AUTOSAR XML (schema 00044)
package /VehicleProject
  system System
    system mapping System_MPPNG
      data-mappings:
        data-element=VehSpd.VehSpd, system-signal=VehSpd
        data-element=Hr.Hr, system-signal=Hr
        data-element=Mth.Mth, system-signal=Mth
        data-element=ComfEna.ComfEna, system-signal=ComfEna
        data-element=VehState.VehState, system-signal=VehState
        data-element=Yr.Yr, system-signal=Yr
        data-element=CGW_03_CRC.CGW_03_CRC, system-signal=CGW_03_CRC
        data-element=WLCChrgFctEnaReq.WLCChrgFctEnaReq, system-signal=WLCChrgFctEnaReq
        data-element=Day.Day, system-signal=Day
        data-element=CGW_03_MsgCntr.CGW_03_MsgCntr, system-signal=CGW_03_MsgCntr
        system-signal=VehSpd
        data-element=Sec.Sec, system-signal=Sec
        data-element=VehOdometer.VehOdometer, system-signal=VehOdometer
        data-element=Min.Min, system-signal=Min
        data-element=VehState_ASIL.VehState_ASIL, system-signal=VehState_ASIL
        data-element=ComfEna_ASIL.ComfEna_ASIL, system-signal=ComfEna_ASIL
        data-element=ImobEnaReq.ImobEnaReq, system-signal=ImobEnaReq
        data-element=CGW_WLC_MsgCntr.CGW_WLC_MsgCntr, system-signal=CGW_WLC_MsgCntr
        data-element=CGW_WLC_CRC.CGW_WLC_CRC, system-signal=CGW_WLC_CRC
        data-element=WLC_02_CRC, system-signal=WLC_02_CRC
        data-element=WLCImobSts.WLCImobSts, system-signal=WLCImobSts
        data-element=UsrData0_WLC.UsrData0_WLC, system-signal=UsrData0_WLC
        data-element=WLC_01_MsgCntr.WLC_01_MsgCntr, system-signal=WLC_01_MsgCntr
        data-element=WLCChrgSts.WLCChrgSts, system-signal=WLCChrgSts
        data-element=WLCCtrlSts.WLCCtrlSts, system-signal=WLCCtrlSts
        data-element=WLC_02_MsgCntr.WLC_02_MsgCntr, system-signal=WLC_02_MsgCntr
        data-element=UsrData4_WLC.UsrData4_WLC, system-signal=UsrData4_WLC
        data-element=UsrData3_WLC.UsrData3_WLC, system-signal=UsrData3_WLC
        data-element=UsrData1_WLC.UsrData1_WLC, system-signal=UsrData1_WLC
        data-element=WLCFailSts.WLCFailSts, system-signal=WLCFailSts
        data-element=WLC_01_CRC.WLC_01_CRC, system-signal=WLC_01_CRC
        data-element=WLCMuteViaHW.WLCMuteViaHW, system-signal=WLCMuteViaHW
        data-element=UsrData2_WLC.UsrData2_WLC, system-signal=UsrData2_WLC
        data-element=UsrData5_WLC.UsrData5_WLC, system-signal=UsrData5_WLC
        data-element=WLCChrgRate.WLCChrgRate, system-signal=WLCChrgRate
    root-software-compositions:
      root sw composition prototype EcuSwComposition: software-composition=ECU_Composition
package /ECUCompositionTypes
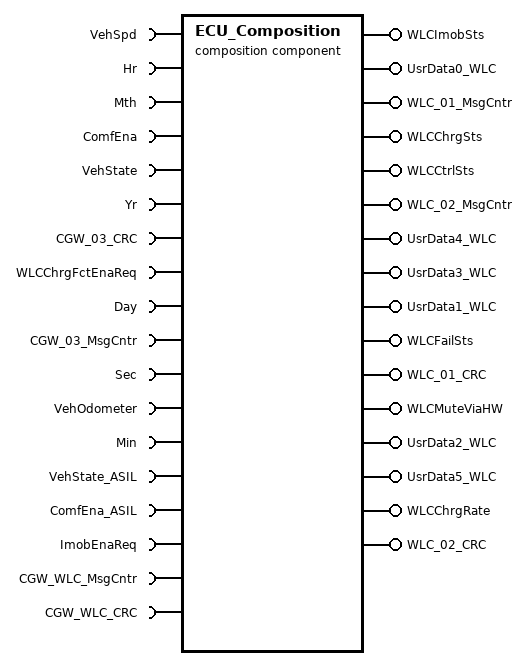
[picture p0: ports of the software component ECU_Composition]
  composition sw component type ECU_Composition
    18 x require port:
      VehSpd: nonqueued-receiver-com-spec{data-element=VehSpd, init-value=0}, required-interface=VehSpd
      Hr: nonqueued-receiver-com-spec{data-element=Hr, init-value=0}, required-interface=Hr
      Mth: nonqueued-receiver-com-spec{data-element=Mth, init-value=0}, required-interface=Mth
      ComfEna: nonqueued-receiver-com-spec{data-element=ComfEna, init-value=0}, required-interface=ComfEna
      VehState: nonqueued-receiver-com-spec{data-element=VehState, init-value=0}, required-interface=VehState
      Yr: nonqueued-receiver-com-spec{data-element=Yr, init-value=0}, required-interface=Yr
      CGW_03_CRC: nonqueued-receiver-com-spec{data-element=CGW_03_CRC, init-value=0}, required-interface=CGW_03_CRC
      WLCChrgFctEnaReq: nonqueued-receiver-com-spec{data-element=WLCChrgFctEnaReq, init-value=0}, required-interface=WLCChrgFctEnaReq
      Day: nonqueued-receiver-com-spec{data-element=Day, init-value=0}, required-interface=Day
      CGW_03_MsgCntr: nonqueued-receiver-com-spec{data-element=CGW_03_MsgCntr, init-value=0}, required-interface=CGW_03_MsgCntr
      Sec: nonqueued-receiver-com-spec{data-element=Sec, init-value=0}, required-interface=Sec
      VehOdometer: nonqueued-receiver-com-spec{data-element=VehOdometer, init-value=0}, required-interface=VehOdometer
      Min: nonqueued-receiver-com-spec{data-element=Min, init-value=0}, required-interface=Min
      VehState_ASIL: nonqueued-receiver-com-spec{data-element=VehState_ASIL, init-value=0}, required-interface=VehState_ASIL
      ComfEna_ASIL: nonqueued-receiver-com-spec{data-element=ComfEna_ASIL, init-value=0}, required-interface=ComfEna_ASIL
      ImobEnaReq: nonqueued-receiver-com-spec{data-element=ImobEnaReq, init-value=0}, required-interface=ImobEnaReq
      CGW_WLC_MsgCntr: nonqueued-receiver-com-spec{data-element=CGW_WLC_MsgCntr, init-value=0}, required-interface=CGW_WLC_MsgCntr
      CGW_WLC_CRC: nonqueued-receiver-com-spec{data-element=CGW_WLC_CRC, init-value=0}, required-interface=CGW_WLC_CRC
    16 x provide port:
      WLCImobSts: nonqueued-sender-com-spec{data-element=WLCImobSts, init-value=0}, provided-interface=WLCImobSts
      UsrData0_WLC: nonqueued-sender-com-spec{data-element=UsrData0_WLC, init-value=0}, provided-interface=UsrData0_WLC
      WLC_01_MsgCntr: nonqueued-sender-com-spec{data-element=WLC_01_MsgCntr, init-value=0}, provided-interface=WLC_01_MsgCntr
      WLCChrgSts: nonqueued-sender-com-spec{data-element=WLCChrgSts, init-value=0}, provided-interface=WLCChrgSts
      WLCCtrlSts: nonqueued-sender-com-spec{data-element=WLCCtrlSts, init-value=0}, provided-interface=WLCCtrlSts
      WLC_02_MsgCntr: nonqueued-sender-com-spec{data-element=WLC_02_MsgCntr, init-value=0}, provided-interface=WLC_02_MsgCntr
      UsrData4_WLC: nonqueued-sender-com-spec{data-element=UsrData4_WLC, init-value=0}, provided-interface=UsrData4_WLC
      UsrData3_WLC: nonqueued-sender-com-spec{data-element=UsrData3_WLC, init-value=0}, provided-interface=UsrData3_WLC
      UsrData1_WLC: nonqueued-sender-com-spec{data-element=UsrData1_WLC, init-value=0}, provided-interface=UsrData1_WLC
      WLCFailSts: nonqueued-sender-com-spec{data-element=WLCFailSts, init-value=0}, provided-interface=WLCFailSts
      WLC_01_CRC: nonqueued-sender-com-spec{data-element=WLC_01_CRC, init-value=0}, provided-interface=WLC_01_CRC
      WLCMuteViaHW: nonqueued-sender-com-spec{data-element=WLCMuteViaHW, init-value=0}, provided-interface=WLCMuteViaHW
      UsrData2_WLC: nonqueued-sender-com-spec{data-element=UsrData2_WLC, init-value=0}, provided-interface=UsrData2_WLC
      UsrData5_WLC: nonqueued-sender-com-spec{data-element=UsrData5_WLC, init-value=0}, provided-interface=UsrData5_WLC
      WLCChrgRate: nonqueued-sender-com-spec{data-element=WLCChrgRate, init-value=0}, provided-interface=WLCChrgRate
      WLC_02_CRC: nonqueued-sender-com-spec=WLC_02_CRC, provided-interface=WLC_02_CRC
    component SWC_WLCAPP: type=SWC_WLCAPP
    component Communication_Read_APP: type=Communication_Read_APP
    delegate Communication_Read_APP.Yr <-> outer port Yr
    delegate Communication_Read_APP.Hr <-> outer port Hr
    delegate Communication_Read_APP.Min <-> outer port Min
    delegate Communication_Read_APP.WLCChrgFctEnaReq <-> outer port WLCChrgFctEnaReq
    delegate Communication_Read_APP.ImobEnaReq <-> outer port ImobEnaReq
    delegate Communication_Read_APP.CGW_WLC_MsgCntr <-> outer port CGW_WLC_MsgCntr
    delegate Communication_Read_APP.VehOdometer <-> outer port VehOdometer
    delegate Communication_Read_APP.CGW_WLC_CRC <-> outer port CGW_WLC_CRC
    delegate Communication_Read_APP.CGW_03_MsgCntr <-> outer port CGW_03_MsgCntr
    delegate Communication_Read_APP.ComfEna_ASIL <-> outer port ComfEna_ASIL
    delegate Communication_Read_APP.VehState_ASIL <-> outer port VehState_ASIL
    delegate Communication_Read_APP.VehState <-> outer port VehState
    delegate Communication_Read_APP.CGW_03_CRC <-> outer port CGW_03_CRC
    delegate Communication_Read_APP.ComfEna <-> outer port ComfEna
    delegate Communication_Read_APP.Day <-> outer port Day
    delegate Communication_Read_APP.Mth <-> outer port Mth
    delegate Communication_Read_APP.Sec <-> outer port Sec
    delegate Communication_Read_APP.VehSpd <-> outer port VehSpd
    delegate Communication_Read_APP.WLC_02_CRC <-> outer port WLC_02_CRC
    delegate Communication_Read_APP.UsrData5_WLC <-> outer port UsrData5_WLC
    delegate Communication_Read_APP.WLCCtrlSts <-> outer port WLCCtrlSts
    delegate Communication_Read_APP.UsrData4_WLC <-> outer port UsrData4_WLC
    delegate Communication_Read_APP.UsrData0_WLC <-> outer port UsrData0_WLC
    delegate Communication_Read_APP.WLCFailSts <-> outer port WLCFailSts
    delegate Communication_Read_APP.UsrData3_WLC <-> outer port UsrData3_WLC
    delegate Communication_Read_APP.WLCMuteViaHW <-> outer port WLCMuteViaHW
    delegate Communication_Read_APP.WLC_01_CRC <-> outer port WLC_01_CRC
    delegate Communication_Read_APP.WLCImobSts <-> outer port WLCImobSts
    delegate Communication_Read_APP.WLC_02_MsgCntr <-> outer port WLC_02_MsgCntr
    delegate Communication_Read_APP.UsrData2_WLC <-> outer port UsrData2_WLC
    delegate Communication_Read_APP.WLCChrgRate <-> outer port WLCChrgRate
    delegate Communication_Read_APP.WLCChrgSts <-> outer port WLCChrgSts
    delegate Communication_Read_APP.UsrData1_WLC <-> outer port UsrData1_WLC
    delegate Communication_Read_APP.WLC_01_MsgCntr <-> outer port WLC_01_MsgCntr
package /EndToEndProtections
  end to end protection set EndToEndProtectionSet
